VERSION "HIPBNYYYYYYYYYYYYYYYYYYYYYYYYYYYYYYYYYYYYY/4/%%%/4/'%**4YYY///"

NS_ :

BS_:

BU_:

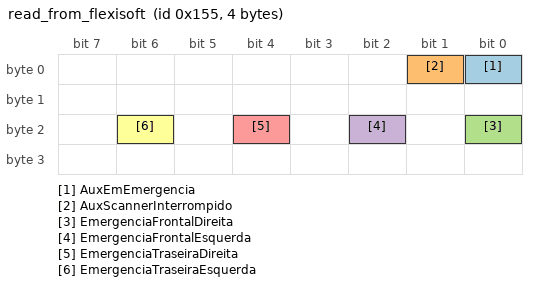
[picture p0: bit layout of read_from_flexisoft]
BO_ 341 read_from_flexisoft: 4 Vector__XXX
 SG_ AuxEmEmergencia : 0|1@1+ (1,0) [0|1] "" Vector__XXX
 SG_ AuxScannerInterrompido : 1|1@1+ (1,0) [0|1] "" Vector__XXX
 SG_ EmergenciaFrontalDireita : 16|1@1+ (1,0) [0|1] "" Vector__XXX
 SG_ EmergenciaFrontalEsquerda : 18|1@1+ (1,0) [0|1] "" Vector__XXX
 SG_ EmergenciaTraseiraDireita : 20|1@1+ (1,0) [0|1] "" Vector__XXX
 SG_ EmergenciaTraseiraEsquerda : 22|1@1+ (1,0) [0|1] "" Vector__XXX

BO_ 342 write_to_flexisoft: 4 Vector__XXX

VAL_ 341 AuxEmEmergencia 0 "stop" 1 "free_to_run" ;
VAL_ 341 AuxScannerInterrompido 0 "free_to_run" 1 "blocked" ;
VAL_ 341 EmergenciaFrontalDireita 0 "pressed" 1 "released" ;
VAL_ 341 EmergenciaFrontalEsquerda 0 "pressed" 1 "released" ;
VAL_ 341 EmergenciaTraseiraDireita 0 "pressed" 1 "released" ;
VAL_ 341 EmergenciaTraseiraEsquerda 0 "pressed" 1 "released" ;
